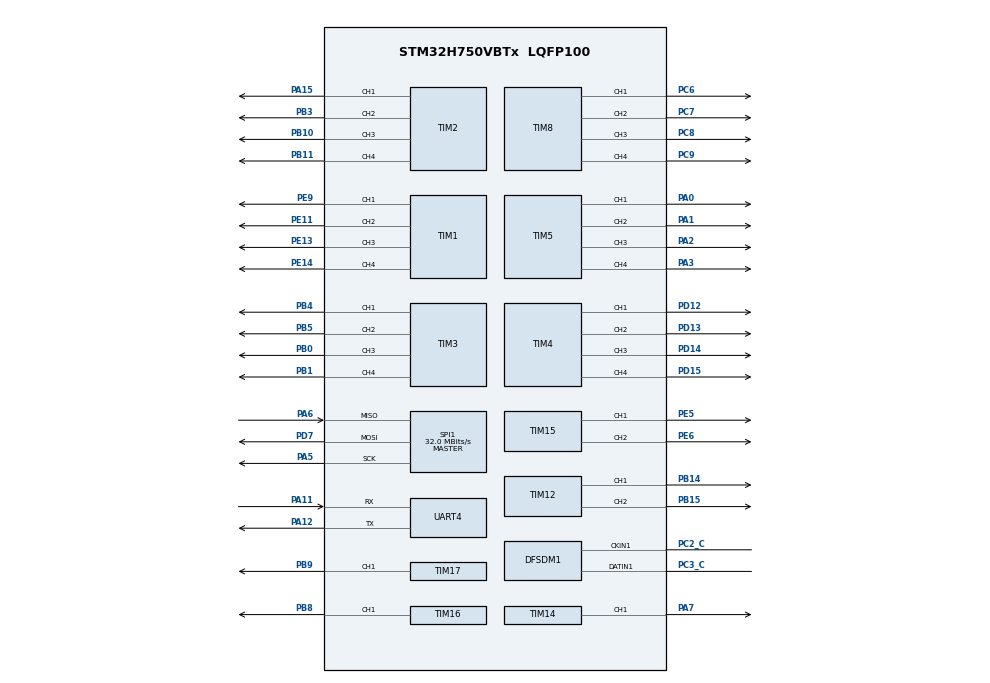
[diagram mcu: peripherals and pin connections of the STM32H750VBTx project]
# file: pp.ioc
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PD7.Mode=Full_Duplex_Master
VP_TIM5_VS_ClockSourceINT.Mode=Internal
SH.S_TIM1_CH4.0=TIM1_CH4,PWM Generation4 CH4
VP_TIM17_VS_ClockSourceINT.Mode=Enable_Timer
SPI1.VirtualType=VM_MASTER
RCC.PLL2_VCI_Range-AdvancedSettings=RCC_PLL2VCIRANGE_0
RCC.PLLFRACN=4096
TIM8.Channel-PWM\ Generation4\ CH4=TIM_CHANNEL_4
PA15\ (JTDI).Signal=S_TIM2_CH1
TIM3.Channel-PWM\ Generation4\ CH4=TIM_CHANNEL_4
RCC.SYSCLKSource=RCC_SYSCLKSOURCE_PLLCLK
RCC.SPI123CLockSelection=RCC_SPI123CLKSOURCE_CLKP
SH.S_TIM14_CH1.0=TIM14_CH1,PWM Generation1 CH1
SPI1.Direction=SPI_DIRECTION_2LINES
PC7.Signal=S_TIM8_CH2
SPI1.CalculateBaudRate=32.0 MBits/s
PE5.Signal=S_TIM15_CH1
TIM4.Channel-PWM\ Generation3\ CH3=TIM_CHANNEL_3
TIM17.Channel=TIM_CHANNEL_1
RCC.DIVM3=42
RCC.DIVM1=4
SH.S_TIM12_CH1.0=TIM12_CH1,PWM Generation1 CH1
TIM1.Channel-PWM\ Generation1\ CH1=TIM_CHANNEL_1
TIM15.Channel-PWM\ Generation2\ CH2=TIM_CHANNEL_2
PE9.Signal=S_TIM1_CH1
SH.S_TIM4_CH2.0=TIM4_CH2,PWM Generation2 CH2
VP_TIM1_VS_ClockSourceINT.Mode=Internal
PA0.Signal=S_TIM5_CH1
Mcu.Package=LQFP100
PB9.Signal=S_TIM17_CH1
PB1.Signal=S_TIM3_CH4
TIM8.Channel-PWM\ Generation3\ CH3=TIM_CHANNEL_3
SH.S_TIM8_CH4.0=TIM8_CH4,PWM Generation4 CH4
PD12.Signal=S_TIM4_CH1
SH.S_TIM12_CH2.0=TIM12_CH2,PWM Generation2 CH2
SH.S_TIM4_CH1.0=TIM4_CH1,PWM Generation1 CH1
RCC.APB4Freq_Value=100000000
VP_TIM14_VS_ClockSourceINT.Mode=Enable_Timer
TIM4.Channel-PWM\ Generation4\ CH4=TIM_CHANNEL_4
PH0-OSC_IN\ (PH0).Mode=HSE-External-Oscillator
PD15.Signal=S_TIM4_CH4
TIM15.Channel-PWM\ Generation1\ CH1=TIM_CHANNEL_1
PA5.Mode=Full_Duplex_Master
SH.S_TIM8_CH3.0=TIM8_CH3,PWM Generation3 CH3
VP_CRYP_VS_CRYP.Mode=CRYP_Activate
PC6.Signal=S_TIM8_CH1
PD7.Signal=SPI1_MOSI
SH.S_TIM16_CH1.0=TIM16_CH1,PWM Generation1 CH1
VP_TIM16_VS_ClockSourceINT.Mode=Enable_Timer
TIM5.Channel-PWM\ Generation3\ CH3=TIM_CHANNEL_3
SH.S_TIM8_CH2.0=TIM8_CH2,PWM Generation2 CH2
TIM3.Channel-PWM\ Generation3\ CH3=TIM_CHANNEL_3
RCC.DIVN3=5
TIM1.Channel-PWM\ Generation2\ CH2=TIM_CHANNEL_2
RCC.DIVN1=12
VP_TIM8_VS_ClockSourceINT.Mode=Internal
PB10.Signal=S_TIM2_CH3
PB14.Signal=S_TIM12_CH1
PA5.Signal=SPI1_SCK
SH.S_TIM8_CH1.0=TIM8_CH1,PWM Generation1 CH1
SH.S_TIM15_CH1.0=TIM15_CH1,PWM Generation1 CH1
PE14.Signal=S_TIM1_CH4
TIM14.Channel=TIM_CHANNEL_1
SPI1.Mode=SPI_MODE_MASTER
TIM5.Channel-PWM\ Generation2\ CH2=TIM_CHANNEL_2
PB5.Signal=S_TIM3_CH2
UART4.OneBitSampling=UART_ONE_BIT_SAMPLE_ENABLE
PA11.Signal=UART4_RX
TIM5.Channel-PWM\ Generation1\ CH1=TIM_CHANNEL_1
ProjectManager.HeapSize=0x200
SH.S_CKIN1DFSDM1.0=DFSDM1_CKIN1,PDM_SPI_input_from_ch1_and_external_clock
VP_TIM4_VS_ClockSourceINT.Mode=Internal
SH.S_TIM17_CH1.0=TIM17_CH1,Output Compare1 CH1
NVIC.PriorityGroup=NVIC_PRIORITYGROUP_4
TIM3.Channel-PWM\ Generation2\ CH2=TIM_CHANNEL_2
TIM1.Channel-PWM\ Generation3\ CH3=TIM_CHANNEL_3
PB0.Signal=S_TIM3_CH3
Mcu.Family=STM32H7
PA6.Mode=Full_Duplex_Master
RCC.CortexFreq_Value=100000000
PH0-OSC_IN\ (PH0).Signal=RCC_OSC_IN
TIM12.Channel-PWM\ Generation2\ CH2=TIM_CHANNEL_2
SH.S_TIM5_CH2.0=TIM5_CH2,PWM Generation2 CH2
PA11.Mode=Asynchronous
TIM2.Channel-PWM\ Generation2\ CH2=TIM_CHANNEL_2
PB11.Signal=S_TIM2_CH4
PB15.Signal=S_TIM12_CH2
ProjectManager.StackSize=0x400
SH.S_TIM15_CH2.0=TIM15_CH2,PWM Generation2 CH2
PD13.Signal=S_TIM4_CH2
PA12.Signal=UART4_TX
TIM1.Channel-PWM\ Generation4\ CH4=TIM_CHANNEL_4
RCC.HCLKFreq_Value=100000000
TIM8.Channel-PWM\ Generation1\ CH1=TIM_CHANNEL_1
SH.S_TIM5_CH3.0=TIM5_CH3,PWM Generation3 CH3
PC2_C.Signal=S_CKIN1DFSDM1
TIM3.Channel-PWM\ Generation1\ CH1=TIM_CHANNEL_1
RCC.HSE_VALUE=25000000
PH1-OSC_OUT\ (PH1).Mode=HSE-External-Oscillator
RCC.PLL1_VCI_Range-AdvancedSettings=RCC_PLL1VCIRANGE_1
PE13.Signal=S_TIM1_CH3
TIM5.Channel-PWM\ Generation4\ CH4=TIM_CHANNEL_4
VP_TIM12_VS_ClockSourceINT.Mode=Internal
TIM2.Channel-PWM\ Generation1\ CH1=TIM_CHANNEL_1
SH.S_TIM3_CH1.0=TIM3_CH1,PWM Generation1 CH1
RCC.APB3Freq_Value=50000000
PA6.Signal=SPI1_MISO
RCC.D1PPRE=RCC_APB3_DIV2
TIM8.Channel-PWM\ Generation2\ CH2=TIM_CHANNEL_2
SH.S_TIM5_CH1.0=TIM5_CH1,PWM Generation1 CH1
SPI1.BaudRatePrescaler=SPI_BAUDRATEPRESCALER_2
SH.S_DATAIN1DFSDM1.0=DFSDM1_DATIN1,PDM_SPI_input_from_ch1_and_external_clock
VP_TIM3_VS_ClockSourceINT.Mode=Internal
PA3.Signal=S_TIM5_CH4
TIM4.Channel-PWM\ Generation1\ CH1=TIM_CHANNEL_1
TIM2.Channel-PWM\ Generation4\ CH4=TIM_CHANNEL_4
SH.S_TIM2_CH1.0=TIM2_CH1,PWM Generation1 CH1
SH.S_TIM4_CH4.0=TIM4_CH4,PWM Generation4 CH4
PC8.Signal=S_TIM8_CH3
RCC.D2PPRE2=RCC_APB2_DIV2
RCC.D2PPRE1=RCC_APB1_DIV2
VP_RNG_VS_RNG.Mode=RNG_Activate
SH.S_TIM3_CH3.0=TIM3_CH3,PWM Generation3 CH3
TIM16.Channel=TIM_CHANNEL_1
PH1-OSC_OUT\ (PH1).Signal=RCC_OSC_OUT
SH.S_TIM2_CH2.0=TIM2_CH2,PWM Generation2 CH2
SH.S_TIM1_CH1.0=TIM1_CH1,PWM Generation1 CH1
PB3\ (JTDO/TRACESWO).Signal=S_TIM2_CH2
ProjectManager.TargetToolchain=STM32CubeIDE
SH.S_TIM4_CH3.0=TIM4_CH3,PWM Generation3 CH3
RCC.USBFreq_Value=100000000
PE11.Signal=S_TIM1_CH2
PA1.Signal=S_TIM5_CH2
SH.S_TIM3_CH2.0=TIM3_CH2,PWM Generation2 CH2
board=custom
TIM12.Channel-PWM\ Generation1\ CH1=TIM_CHANNEL_1
TIM4.Channel-PWM\ Generation2\ CH2=TIM_CHANNEL_2
RCC.APB2Freq_Value=50000000
VP_HASH_VS_HASH.Mode=HASH_Activate
SH.S_TIM1_CH2.0=TIM1_CH2,PWM Generation2 CH2
VP_TIM2_VS_ClockSourceINT.Mode=Internal
SH.S_TIM2_CH3.0=TIM2_CH3,PWM Generation3 CH3
RCC.ADCFreq_Value=129000000
TIM2.Channel-PWM\ Generation3\ CH3=TIM_CHANNEL_3
SH.S_TIM5_CH4.0=TIM5_CH4,PWM Generation4 CH4
PE6.Signal=S_TIM15_CH2
Mcu.Name=STM32H750VBTx
PA2.Signal=S_TIM5_CH3
PD14.Signal=S_TIM4_CH3
RCC.SYSCLKFreq_VALUE=100000000
PA12.Mode=Asynchronous
VP_TIM15_VS_ClockSourceINT.Mode=Internal
SH.S_TIM2_CH4.0=TIM2_CH4,PWM Generation4 CH4
SH.S_TIM1_CH3.0=TIM1_CH3,PWM Generation3 CH3
PC3_C.Signal=S_DATAIN1DFSDM1
PB8.Signal=S_TIM16_CH1
PC9.Signal=S_TIM8_CH4
RCC.APB1Freq_Value=50000000
SH.S_TIM3_CH4.0=TIM3_CH4,PWM Generation4 CH4
PA7.Signal=S_TIM14_CH1
PB4\ (NJTRST).Signal=S_TIM3_CH1

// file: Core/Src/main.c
/* USER CODE BEGIN Header */
/**
  ******************************************************************************
  * @file           : main.c
  * @brief          : Main program body
  ******************************************************************************
  * @attention
  *
  * <h2><center>&copy; Copyright (c) 2021 STMicroelectronics.
  * All rights reserved.</center></h2>
  *
  * This software component is licensed by ST under BSD 3-Clause license,
  * the "License"; You may not use this file except in compliance with the
  * License. You may obtain a copy of the License at:
  *                        opensource.org/licenses/BSD-3-Clause
  *
  ******************************************************************************
  */
/* USER CODE END Header */
#include "main.h"
#include "cryp.h"
#include "dfsdm.h"
#include "hash.h"
#include "rng.h"
#include "spi.h"
#include "tim.h"
#include "usart.h"
#include "gpio.h"

void SystemClock_Config(void);
void PeriphCommonClock_Config(void);

int main(void)
{

  /* MCU Configuration--------------------------------------------------------*/

  /* Reset of all peripherals, Initializes the Flash interface and the Systick. */
  HAL_Init();

  /* Configure the system clock */
  SystemClock_Config();

/* Configure the peripherals common clocks */
  PeriphCommonClock_Config();

  /* Initialize all configured peripherals */
  MX_GPIO_Init();
  MX_CRYP_Init();
  MX_DFSDM1_Init();
  MX_HASH_Init();
  MX_RNG_Init();
  MX_SPI1_Init();
  MX_TIM1_Init();
  MX_TIM2_Init();
  MX_TIM3_Init();
  MX_TIM4_Init();
  MX_TIM5_Init();
  MX_TIM8_Init();
  MX_TIM12_Init();
  MX_TIM14_Init();
  MX_TIM15_Init();
  MX_TIM16_Init();
  MX_TIM17_Init();
  MX_UART4_Init();

  /* Infinite loop */
  /* USER CODE BEGIN WHILE */
  while (1)
  {
	 int k=0;
	 for(int s=0;s<100;s++){
		 k+=s;
		 int lalala=s+k;
	 }

    /* USER CODE END WHILE */

  }
}

void SystemClock_Config(void)
{
  RCC_OscInitTypeDef RCC_OscInitStruct = {0};
  RCC_ClkInitTypeDef RCC_ClkInitStruct = {0};

  /** Supply configuration update enable
  */
  HAL_PWREx_ConfigSupply(PWR_LDO_SUPPLY);
  /** Configure the main internal regulator output voltage
  */
  __HAL_PWR_VOLTAGESCALING_CONFIG(PWR_REGULATOR_VOLTAGE_SCALE3);

  while(!__HAL_PWR_GET_FLAG(PWR_FLAG_VOSRDY)) {}
  /** Initializes the RCC Oscillators according to the specified parameters
  * in the RCC_OscInitTypeDef structure.
  */
  RCC_OscInitStruct.OscillatorType = RCC_OSCILLATORTYPE_HSI48|RCC_OSCILLATORTYPE_HSI;
  RCC_OscInitStruct.HSIState = RCC_HSI_DIV1;
  RCC_OscInitStruct.HSICalibrationValue = RCC_HSICALIBRATION_DEFAULT;
  RCC_OscInitStruct.HSI48State = RCC_HSI48_ON;
  RCC_OscInitStruct.PLL.PLLState = RCC_PLL_ON;
  RCC_OscInitStruct.PLL.PLLSource = RCC_PLLSOURCE_HSI;
  RCC_OscInitStruct.PLL.PLLM = 4;
  RCC_OscInitStruct.PLL.PLLN = 12;
  RCC_OscInitStruct.PLL.PLLP = 2;
  RCC_OscInitStruct.PLL.PLLQ = 2;
  RCC_OscInitStruct.PLL.PLLR = 2;
  RCC_OscInitStruct.PLL.PLLRGE = RCC_PLL1VCIRANGE_3;
  RCC_OscInitStruct.PLL.PLLVCOSEL = RCC_PLL1VCOWIDE;
  RCC_OscInitStruct.PLL.PLLFRACN = 4096;
  if (HAL_RCC_OscConfig(&RCC_OscInitStruct) != HAL_OK)
  {
    Error_Handler();
  }
  /** Initializes the CPU, AHB and APB buses clocks
  */
  RCC_ClkInitStruct.ClockType = RCC_CLOCKTYPE_HCLK|RCC_CLOCKTYPE_SYSCLK
                              |RCC_CLOCKTYPE_PCLK1|RCC_CLOCKTYPE_PCLK2
                              |RCC_CLOCKTYPE_D3PCLK1|RCC_CLOCKTYPE_D1PCLK1;
  RCC_ClkInitStruct.SYSCLKSource = RCC_SYSCLKSOURCE_PLLCLK;
  RCC_ClkInitStruct.SYSCLKDivider = RCC_SYSCLK_DIV1;
  RCC_ClkInitStruct.AHBCLKDivider = RCC_HCLK_DIV1;
  RCC_ClkInitStruct.APB3CLKDivider = RCC_APB3_DIV2;
  RCC_ClkInitStruct.APB1CLKDivider = RCC_APB1_DIV2;
  RCC_ClkInitStruct.APB2CLKDivider = RCC_APB2_DIV2;
  RCC_ClkInitStruct.APB4CLKDivider = RCC_APB4_DIV1;

  if (HAL_RCC_ClockConfig(&RCC_ClkInitStruct, FLASH_LATENCY_2) != HAL_OK)
  {
    Error_Handler();
  }
}

void PeriphCommonClock_Config(void)
{
  RCC_PeriphCLKInitTypeDef PeriphClkInitStruct = {0};

  /** Initializes the peripherals clock
  */
  PeriphClkInitStruct.PeriphClockSelection = RCC_PERIPHCLK_CKPER;
  PeriphClkInitStruct.CkperClockSelection = RCC_CLKPSOURCE_HSI;
  if (HAL_RCCEx_PeriphCLKConfig(&PeriphClkInitStruct) != HAL_OK)
  {
    Error_Handler();
  }
}

void Error_Handler(void)
{
  __disable_irq();
  while (1)
  {
  }
}

/************************ (C) COPYRIGHT STMicroelectronics *****END OF FILE****/
